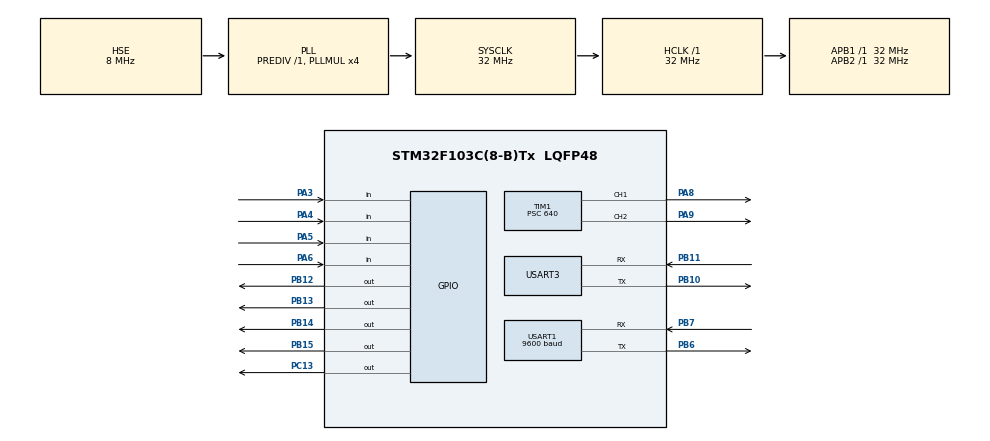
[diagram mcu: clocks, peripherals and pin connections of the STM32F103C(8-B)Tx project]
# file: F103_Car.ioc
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Mcu.Family=STM32F1
Mcu.Name=STM32F103C(8-B)Tx
Mcu.Package=LQFP48
NVIC.PriorityGroup=NVIC_PRIORITYGROUP_4
NVIC.TIM2_IRQn=true\:0\:0\:false\:false\:true\:true\:true
NVIC.USART1_IRQn=true\:0\:0\:false\:false\:true\:true\:true
PA13.Mode=Serial_Wire
PA13.Signal=SYS_JTMS-SWDIO
PA14.Mode=Serial_Wire
PA14.Signal=SYS_JTCK-SWCLK
PA3.Signal=GPIO_Input
PA4.Signal=GPIO_Input
PA5.Signal=GPIO_Input
PA6.Signal=GPIO_Input
PA8.Signal=S_TIM1_CH1
PA9.Signal=S_TIM1_CH2
PB10.Mode=Asynchronous
PB10.Signal=USART3_TX
PB11.Mode=Asynchronous
PB11.Signal=USART3_RX
PB12.GPIO_PuPd=GPIO_PULLUP
PB12.GPIO_Speed=GPIO_SPEED_FREQ_HIGH
PB12.PinState=GPIO_PIN_SET
PB12.Signal=GPIO_Output
PB13.GPIO_PuPd=GPIO_PULLUP
PB13.GPIO_Speed=GPIO_SPEED_FREQ_HIGH
PB13.PinState=GPIO_PIN_SET
PB13.Signal=GPIO_Output
PB14.GPIO_PuPd=GPIO_PULLUP
PB14.GPIO_Speed=GPIO_SPEED_FREQ_HIGH
PB14.PinState=GPIO_PIN_SET
PB14.Signal=GPIO_Output
PB15.GPIO_PuPd=GPIO_PULLUP
PB15.GPIO_Speed=GPIO_SPEED_FREQ_HIGH
PB15.PinState=GPIO_PIN_SET
PB15.Signal=GPIO_Output
PB6.Mode=Asynchronous
PB6.Signal=USART1_TX
PB7.Mode=Asynchronous
PB7.Signal=USART1_RX
PC13-TAMPER-RTC.GPIO_ModeDefaultOutputPP=GPIO_MODE_OUTPUT_PP
PC13-TAMPER-RTC.GPIO_PuPd=GPIO_PULLUP
PC13-TAMPER-RTC.GPIO_Speed=GPIO_SPEED_FREQ_HIGH
PC13-TAMPER-RTC.PinState=GPIO_PIN_SET
PC13-TAMPER-RTC.Signal=GPIO_Output
PD0-OSC_IN.Mode=HSE-External-Oscillator
PD0-OSC_IN.Signal=RCC_OSC_IN
PD1-OSC_OUT.Mode=HSE-External-Oscillator
PD1-OSC_OUT.Signal=RCC_OSC_OUT
ProjectManager.HeapSize=0x200
ProjectManager.StackSize=0x400
ProjectManager.TargetToolchain=MDK-ARM V5
RCC.AHBFreq_Value=32000000
RCC.APB1Freq_Value=32000000
RCC.APB1TimFreq_Value=32000000
RCC.APB2Freq_Value=32000000
RCC.APB2TimFreq_Value=32000000
RCC.HCLKFreq_Value=32000000
RCC.PLLMUL=RCC_PLL_MUL4
RCC.PLLSourceVirtual=RCC_PLLSOURCE_HSE
RCC.SYSCLKFreq_VALUE=32000000
RCC.SYSCLKSource=RCC_SYSCLKSOURCE_PLLCLK
RCC.USBFreq_Value=32000000
SH.S_TIM1_CH1.0=TIM1_CH1,PWM Generation1 CH1
SH.S_TIM1_CH2.0=TIM1_CH2,PWM Generation2 CH2
TIM1.Channel-PWM\ Generation1\ CH1=TIM_CHANNEL_1
TIM1.Channel-PWM\ Generation2\ CH2=TIM_CHANNEL_2
TIM1.Period=1000
TIM1.Prescaler=640
TIM2.Period=999
TIM2.Prescaler=3200-1
USART1.BaudRate=9600
USART1.VirtualMode=VM_ASYNC
USART3.VirtualMode=VM_ASYNC
VP_TIM2_VS_ClockSourceINT.Mode=Internal
board=custom

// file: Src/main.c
/* USER CODE BEGIN Header */
/**
  ******************************************************************************
  * @file           : main.c
  * @brief          : Main program body
  ******************************************************************************
  * @attention
  *
  * <h2><center>&copy; Copyright (c) 2019 STMicroelectronics.
  * All rights reserved.</center></h2>
  *
  * This software component is licensed by ST under BSD 3-Clause license,
  * the "License"; You may not use this file except in compliance with the
  * License. You may obtain a copy of the License at:
  *                        opensource.org/licenses/BSD-3-Clause
  *
  ******************************************************************************
  */
/* USER CODE END Header */

#include "main.h"
#include "tim.h"
#include "usart.h"
#include "gpio.h"

void SystemClock_Config(void);

int main(void)
{

  /* MCU Configuration--------------------------------------------------------*/

  /* Reset of all peripherals, Initializes the Flash interface and the Systick. */
  HAL_Init();

  /* Configure the system clock */
  SystemClock_Config();

  /* Initialize all configured peripherals */
  MX_GPIO_Init();
  MX_TIM1_Init();
  MX_USART1_UART_Init();
  MX_TIM2_Init();
  MX_USART3_UART_Init();
  /* USER CODE BEGIN 2 */
  HAL_TIM_Base_Start_IT(&htim2);
  PWM_Init();
  /* USER CODE END 2 */

  /* Infinite loop */
  while (1)
  {

    /* USER CODE BEGIN 3 */

	  //���������Դ���
/*	  beep_ON();
	  HAL_Delay(1000);
	  beep_OFF();
	  HAL_Delay(1000);   */

  }
  /* USER CODE END 3 */
}

void SystemClock_Config(void)
{
  RCC_OscInitTypeDef RCC_OscInitStruct = {0};
  RCC_ClkInitTypeDef RCC_ClkInitStruct = {0};

  /** Initializes the CPU, AHB and APB busses clocks
  */
  RCC_OscInitStruct.OscillatorType = RCC_OSCILLATORTYPE_HSE;
  RCC_OscInitStruct.HSEState = RCC_HSE_ON;
  RCC_OscInitStruct.HSEPredivValue = RCC_HSE_PREDIV_DIV1;
  RCC_OscInitStruct.HSIState = RCC_HSI_ON;
  RCC_OscInitStruct.PLL.PLLState = RCC_PLL_ON;
  RCC_OscInitStruct.PLL.PLLSource = RCC_PLLSOURCE_HSE;
  RCC_OscInitStruct.PLL.PLLMUL = RCC_PLL_MUL4;
  if (HAL_RCC_OscConfig(&RCC_OscInitStruct) != HAL_OK)
  {
    Error_Handler();
  }
  /** Initializes the CPU, AHB and APB busses clocks
  */
  RCC_ClkInitStruct.ClockType = RCC_CLOCKTYPE_HCLK|RCC_CLOCKTYPE_SYSCLK
                              |RCC_CLOCKTYPE_PCLK1|RCC_CLOCKTYPE_PCLK2;
  RCC_ClkInitStruct.SYSCLKSource = RCC_SYSCLKSOURCE_PLLCLK;
  RCC_ClkInitStruct.AHBCLKDivider = RCC_SYSCLK_DIV1;
  RCC_ClkInitStruct.APB1CLKDivider = RCC_HCLK_DIV1;
  RCC_ClkInitStruct.APB2CLKDivider = RCC_HCLK_DIV1;

  if (HAL_RCC_ClockConfig(&RCC_ClkInitStruct, FLASH_LATENCY_1) != HAL_OK)
  {
    Error_Handler();
  }
}

/* USER CODE BEGIN 4 */
void HAL_TIM_PeriodElapsedCallback(TIM_HandleTypeDef*htim)
{
	if(htim -> Instance == htim2.Instance)
	{
		HAL_GPIO_TogglePin(GPIOC,GPIO_PIN_13);
	}
}
/* USER CODE END 4 */

void Error_Handler(void)
{
}

/************************ (C) COPYRIGHT STMicroelectronics *****END OF FILE****/
